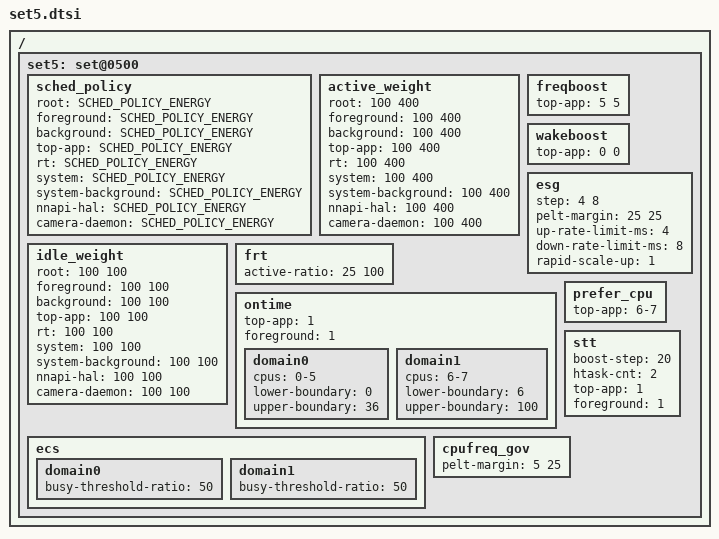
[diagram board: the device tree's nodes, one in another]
/ {
	/* camera mode - default */
	set5: set@0500 {
		/* schedudling policy */
		sched_policy {
			root			= <SCHED_POLICY_ENERGY>;
			foreground 		= <SCHED_POLICY_ENERGY>;
			background		= <SCHED_POLICY_ENERGY>;
			top-app			= <SCHED_POLICY_ENERGY>;
			rt			= <SCHED_POLICY_ENERGY>;
			system			= <SCHED_POLICY_ENERGY>;
			system-background	= <SCHED_POLICY_ENERGY>;
			nnapi-hal		= <SCHED_POLICY_ENERGY>;
			camera-daemon		= <SCHED_POLICY_ENERGY>;
		};

		/* weight (%) applied to active cpu's efficiency */
		active_weight {			/* LIT BIG */
			root			= <100 400>;
			foreground		= <100 400>;
			background		= <100 400>;
			top-app			= <100 400>;
			rt			= <100 400>;
			system			= <100 400>;
			system-background	= <100 400>;
			nnapi-hal		= <100 400>;
			camera-daemon		= <100 400>;
		};

		/* weight (%) applied to idle cpu's efficiency */
		idle_weight {			/* LIT BIG */
			root			= <100 100>;
			foreground		= <100 100>;
			background		= <100 100>;
			top-app			= <100 100>;
			rt			= <100 100>;
			system			= <100 100>;
			system-background	= <100 100>;
			nnapi-hal		= <100 100>;
			camera-daemon		= <100 100>;
		};

		/* Boosting margin applied to frequency selection */
		freqboost {			/* LIT BIG */
			top-app			= < 5   5>;
		};

		/* Boosting margin for waking up task */
		wakeboost {			/* LIT BIG */
			top-app			= < 0   0>;
		};

		/* gov-data used by ESG */
		esg {				/* LIT BIG */
			step			= < 4   8>;
			pelt-margin		= < 25  25>;

			up-rate-limit-ms 	= <4>;
			down-rate-limit-ms 	= <8>;
			rapid-scale-up 		= <1>;
		};

		frt {				/* LIT BIG */
			active-ratio		= < 25 100>;
		};

		/* Ontime Migration */
		ontime {
			top-app		= <1>;
			foreground	= <1>;

			domain0 {
				cpus = "0-5";
				lower-boundary = <0>;
				upper-boundary = <36>;
			};
			domain1 {
				cpus = "6-7";
				lower-boundary = <6>;
				upper-boundary = <100>;
			};
		};

		ecs {
			domain0 {
				busy-threshold-ratio = <50>;
			};
			domain1 {
				busy-threshold-ratio = <50>;
			};
		};

		prefer_cpu {
			top-app = "6-7";
		};

		stt {
			boost-step		= <20>;
			htask-cnt		= <2>;
			top-app			= <1>;
			foreground		= <1>;
		};

		cpufreq_gov {			/* LIT BIG */
			pelt-margin		= < 5   25>;
		};
	};
};
